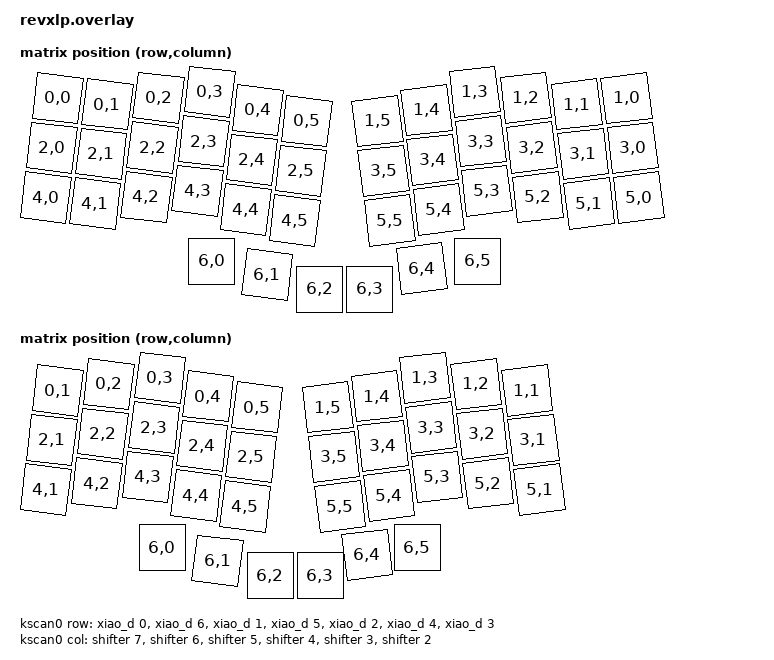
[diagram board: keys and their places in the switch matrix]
/*
 * Copyright (c) 2020 The ZMK Contributors
 *
 * SPDX-License-Identifier: MIT
 */

#include <dt-bindings/zmk/matrix_transform.h>
#include <physical_layouts.dtsi>

&xiao_serial { status = "disabled"; };

&xiao_spi {
	status = "okay";
	cs-gpios = <&xiao_d 9 GPIO_ACTIVE_LOW>;
	shifter: 595@0 {
		compatible = "zmk,gpio-595";
		status = "okay";
		gpio-controller;
		spi-max-frequency = <200000>;
		reg = <0>;
		#gpio-cells = <2>;
		ngpios = <8>;
	};
};

/ {
	chosen {
		zmk,backlight = &backlight;
		zmk,physical-layout = &twelve_u_layout;
		zmk,kscan = &kscan0;
	};

	backlight: backlight_leds {
		compatible = "gpio-leds";
		led_mosfet {
			gpios = <&xiao_d 7 GPIO_ACTIVE_LOW>;
		};
	};

	twelve_u_transform: keymap_transform_12u {
		compatible = "zmk,matrix-transform";

		columns = <6>;
		rows = <7>;
	
		map = <
RC(0,0) RC(0,1) RC(0,2) RC(0,3) RC(0,4) RC(0,5) RC(1,5) RC(1,4) RC(1,3) RC(1,2) RC(1,1) RC(1,0)
RC(2,0) RC(2,1) RC(2,2) RC(2,3) RC(2,4) RC(2,5) RC(3,5) RC(3,4) RC(3,3) RC(3,2) RC(3,1) RC(3,0)
RC(4,0) RC(4,1) RC(4,2) RC(4,3) RC(4,4) RC(4,5) RC(5,5) RC(5,4) RC(5,3) RC(5,2) RC(5,1) RC(5,0)
                RC(6,0) RC(6,1) RC(6,2)  RC(6,3) RC(6,4) RC(6,5)
		>;
	};

	ten_u_transform: keymap_transform_10u {
		compatible = "zmk,matrix-transform";

		columns = <6>;
		rows = <7>;
	
		map = <
        RC(0,1) RC(0,2) RC(0,3) RC(0,4) RC(0,5) RC(1,5) RC(1,4) RC(1,3) RC(1,2) RC(1,1)
        RC(2,1) RC(2,2) RC(2,3) RC(2,4) RC(2,5) RC(3,5) RC(3,4) RC(3,3) RC(3,2) RC(3,1)
        RC(4,1) RC(4,2) RC(4,3) RC(4,4) RC(4,5) RC(5,5) RC(5,4) RC(5,3) RC(5,2) RC(5,1)
                RC(6,0) RC(6,1) RC(6,2)  RC(6,3) RC(6,4) RC(6,5)
		>;
	};

	kscan0: kscan_0 {
		compatible = "zmk,kscan-gpio-matrix";
		diode-direction = "col2row";
		
		col-gpios
			= <&shifter 7 GPIO_ACTIVE_HIGH>
			, <&shifter 6 GPIO_ACTIVE_HIGH>
			, <&shifter 5 GPIO_ACTIVE_HIGH>
			, <&shifter 4 GPIO_ACTIVE_HIGH>
			, <&shifter 3 GPIO_ACTIVE_HIGH>
			, <&shifter 2 GPIO_ACTIVE_HIGH>
			;
		
		row-gpios
			= <&xiao_d 0 (GPIO_ACTIVE_HIGH | GPIO_PULL_DOWN)>
			, <&xiao_d 6 (GPIO_ACTIVE_HIGH | GPIO_PULL_DOWN)>
			, <&xiao_d 1 (GPIO_ACTIVE_HIGH | GPIO_PULL_DOWN)>
			, <&xiao_d 5 (GPIO_ACTIVE_HIGH | GPIO_PULL_DOWN)>
			, <&xiao_d 2 (GPIO_ACTIVE_HIGH | GPIO_PULL_DOWN)>
			, <&xiao_d 4 (GPIO_ACTIVE_HIGH | GPIO_PULL_DOWN)>
			, <&xiao_d 3 (GPIO_ACTIVE_HIGH | GPIO_PULL_DOWN)>
			;
	};

	ten_u_layout: ten_u_layout {
		compatible = "zmk,physical-layout";
		display-name = "10u";
		
		transform = <&ten_u_transform>;
		
		keys
			= <&key_physical_attrs 100 100 000  53   700  300 338>
			, <&key_physical_attrs 100 100 100  28   700  300 338>
			, <&key_physical_attrs 100 100 200  03   700  300 338>
			, <&key_physical_attrs 100 100 300  28   700  300 338>
			, <&key_physical_attrs 100 100 400  38   700  300 338>
			, <&key_physical_attrs 100 100 600  38 (-700) 800 338>
			, <&key_physical_attrs 100 100 700  28 (-700) 800 338>
			, <&key_physical_attrs 100 100 800  03 (-700) 800 338>
			, <&key_physical_attrs 100 100 900  28 (-700) 800 338>
			, <&key_physical_attrs 100 100 1000 53 (-700) 800 338>

			, <&key_physical_attrs 100 100 000  153   700  300 338>
			, <&key_physical_attrs 100 100 100  128   700  300 338>
			, <&key_physical_attrs 100 100 200  103   700  300 338>
			, <&key_physical_attrs 100 100 300  128   700  300 338>
			, <&key_physical_attrs 100 100 400  138   700  300 338>
			, <&key_physical_attrs 100 100 600  138 (-700) 800 338>
			, <&key_physical_attrs 100 100 700  128 (-700) 800 338>
			, <&key_physical_attrs 100 100 800  103 (-700) 800 338>
			, <&key_physical_attrs 100 100 900  128 (-700) 800 338>
			, <&key_physical_attrs 100 100 1000 153 (-700) 800 338>

			, <&key_physical_attrs 100 100 000  253   700  300 338>
			, <&key_physical_attrs 100 100 100  228   700  300 338>
			, <&key_physical_attrs 100 100 200  203   700  300 338>
			, <&key_physical_attrs 100 100 300  228   700  300 338>
			, <&key_physical_attrs 100 100 400  238   700  300 338>
			, <&key_physical_attrs 100 100 600  238 (-700) 800 338>
			, <&key_physical_attrs 100 100 700  228 (-700) 800 338>
			, <&key_physical_attrs 100 100 800  203 (-700) 800 338>
			, <&key_physical_attrs 100 100 900  228 (-700) 800 338>
			, <&key_physical_attrs 100 100 1000 253 (-700) 800 338>

			, <&key_physical_attrs 100 100 239 338 0 0 0>
			, <&key_physical_attrs 100 100 350 365 700 400 415>
			, <&key_physical_attrs 100 100 455 394 0 0 0>
			, <&key_physical_attrs 100 100 555 394 0 0 0>
			, <&key_physical_attrs 100 100 650 365 (-700) 600 415>
			, <&key_physical_attrs 100 100 749 338 0 0 0>
			;
	};

	twelve_u_layout: twelve_u_layout {
		compatible = "zmk,physical-layout";
		display-name = "12u";
		
		transform = <&twelve_u_transform>;
		
		keys
			= <&key_physical_attrs 100 100 000  53 700    400 338>
			, <&key_physical_attrs 100 100 100  53 700    400 338>
			, <&key_physical_attrs 100 100 200  28 700    400 338>
			, <&key_physical_attrs 100 100 300  03 700    400 338>
			, <&key_physical_attrs 100 100 400  28 700    400 338>
			, <&key_physical_attrs 100 100 500  38 700    400 338>
			, <&key_physical_attrs 100 100 700  38 (-700) 900 338>
			, <&key_physical_attrs 100 100 800  28 (-700) 900 338>
			, <&key_physical_attrs 100 100 900  03 (-700) 900 338>
			, <&key_physical_attrs 100 100 1000 28 (-700) 900 338>
			, <&key_physical_attrs 100 100 1100 53 (-700) 900 338>
			, <&key_physical_attrs 100 100 1200 53 (-700) 900 338>

			, <&key_physical_attrs 100 100 000  153 700    400 338>
			, <&key_physical_attrs 100 100 100  153 700    400 338>
			, <&key_physical_attrs 100 100 200  128 700    400 338>
			, <&key_physical_attrs 100 100 300  103 700    400 338>
			, <&key_physical_attrs 100 100 400  128 700    400 338>
			, <&key_physical_attrs 100 100 500  138 700    400 338>
			, <&key_physical_attrs 100 100 700  138 (-700) 900 338>
			, <&key_physical_attrs 100 100 800  128 (-700) 900 338>
			, <&key_physical_attrs 100 100 900  103 (-700) 900 338>
			, <&key_physical_attrs 100 100 1000 128 (-700) 900 338>
			, <&key_physical_attrs 100 100 1100 153 (-700) 900 338>
			, <&key_physical_attrs 100 100 1200 153 (-700) 900 338>

			, <&key_physical_attrs 100 100 000  253 700    400 338>
			, <&key_physical_attrs 100 100 100  253 700    400 338>
			, <&key_physical_attrs 100 100 200  228 700    400 338>
			, <&key_physical_attrs 100 100 300  203 700    400 338>
			, <&key_physical_attrs 100 100 400  228 700    400 338>
			, <&key_physical_attrs 100 100 500  238 700    400 338>
			, <&key_physical_attrs 100 100 700  238 (-700) 900 338>
			, <&key_physical_attrs 100 100 800  228 (-700) 900 338>
			, <&key_physical_attrs 100 100 900  203 (-700) 900 338>
			, <&key_physical_attrs 100 100 1000 228 (-700) 900 338>
			, <&key_physical_attrs 100 100 1100 253 (-700) 900 338>
			, <&key_physical_attrs 100 100 1200 253 (-700) 900 338>

			, <&key_physical_attrs 100 100 339 338 0 0 0>
			, <&key_physical_attrs 100 100 450 365 700 500 415>
			, <&key_physical_attrs 100 100 555 394 0 0 0>
			, <&key_physical_attrs 100 100 655 394 0 0 0>
			, <&key_physical_attrs 100 100 760 365 (-700) 710 415>
			, <&key_physical_attrs 100 100 871 338 0 0 0>
			;
	};

	pos_map {
		compatible = "zmk,physical-layout-position-map";

		complete;

		twelve {
			physical-layout = <&twelve_u_layout>;
			positions
				= < 0  1  2  3  4  5  6  7  8  9 10 11 >
				, <12 13 14 15 16 17 18 19 20 21 22 23>
				, <24 25 26 27 28 29 30 31 32 33 34 35>
				, <         36 37 38 39 40 41               >;
		};

		ten {
			physical-layout = <&ten_u_layout>;
			positions
				= <36  0  1  2  3  4  5  6  7  8  9 37>
				, <38 10 11 12 13 14 15 16 17 18 19 39>
				, <40 20 21 22 23 24 25 26 27 28 29 41>
				,       <30 31 32 33 34 35>;
		};
	};
};
